# ioam3358 register map
Registers are 32-bit, access not given, no defined reset value unless marked. A register's access mark holds for its fields unless they carry their own. Addresses are absolute; registers are grouped by the start of their names; [hi:lo] are bit positions; {n}, {i} and the like mark numbered series; 'fields as' and 'values as' point back to an identical list.

## PWMSS
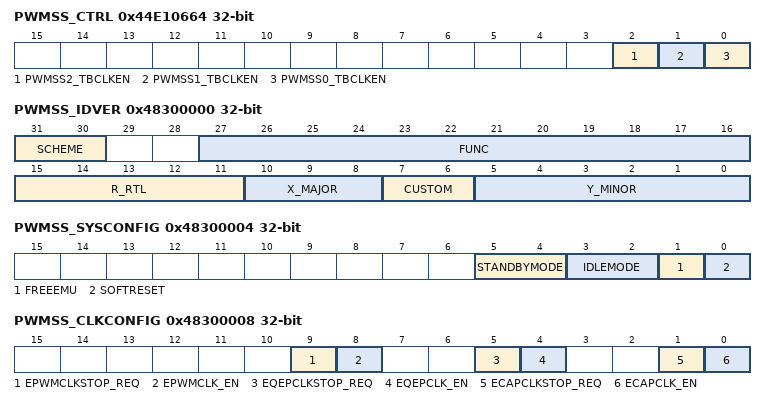
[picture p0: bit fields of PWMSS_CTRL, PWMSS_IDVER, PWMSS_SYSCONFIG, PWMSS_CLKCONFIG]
0x44E10664 PWMSS_CTRL
  [2] PWMSS2_TBCLKEN, [1] PWMSS1_TBCLKEN, [0] PWMSS0_TBCLKEN
0x48300000 PWMSS_IDVER
  [31:30] SCHEME, [27:16] FUNC, [15:11] R_RTL, [10:8] X_MAJOR, [7:6] CUSTOM, [5:0] Y_MINOR
0x48300004 PWMSS_SYSCONFIG
  [5:4] STANDBYMODE, [3:2] IDLEMODE, [1] FREEEMU, [0] SOFTRESET
0x48300008 PWMSS_CLKCONFIG
  [9] EPWMCLKSTOP_REQ, [8] EPWMCLK_EN, [5] EQEPCLKSTOP_REQ, [4] EQEPCLK_EN, [1] ECAPCLKSTOP_REQ, [0] ECAPCLK_EN
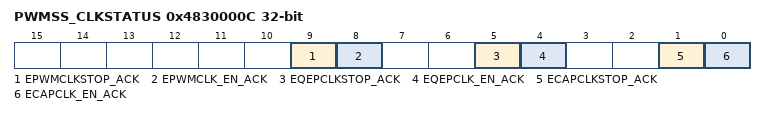
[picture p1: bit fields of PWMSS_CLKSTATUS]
0x4830000C PWMSS_CLKSTATUS
  [9] EPWMCLKSTOP_ACK, [8] EPWMCLK_EN_ACK, [5] EQEPCLKSTOP_ACK, [4] EQEPCLK_EN_ACK, [1] ECAPCLKSTOP_ACK, [0] ECAPCLK_EN_ACK

## MREQPRIO
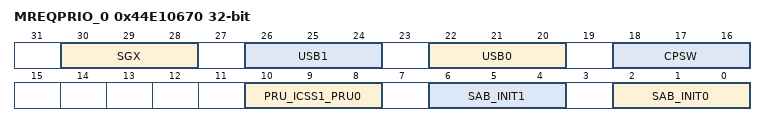
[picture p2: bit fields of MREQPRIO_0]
0x44E10670 MREQPRIO_0
  [30:28] SGX, [26:24] USB1, [22:20] USB0, [18:16] CPSW, [10:8] PRU_ICSS1_PRU0, [6:4] SAB_INIT1, [2:0] SAB_INIT0
0x44E10674 MREQPRIO_1
  [2:0] EXP

## HW
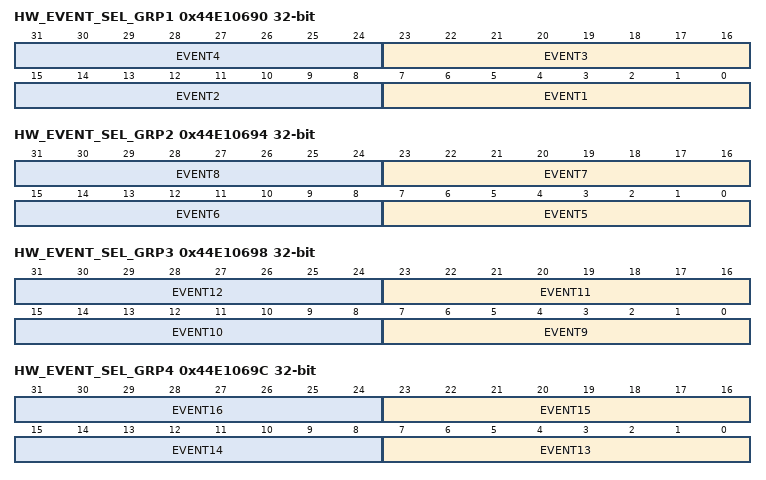
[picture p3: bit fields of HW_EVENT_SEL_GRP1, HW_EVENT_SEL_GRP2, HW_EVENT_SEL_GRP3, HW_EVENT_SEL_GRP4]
0x44E10690 HW_EVENT_SEL_GRP1
  [8n-1:8n-8] EVENT{n} (n=1..4)
0x44E10694 HW_EVENT_SEL_GRP2
  [8n-33:8n-40] EVENT{n} (n=5..8)
0x44E10698 HW_EVENT_SEL_GRP3
  [8n-65:8n-72] EVENT{n} (n=9..12)
0x44E1069C HW_EVENT_SEL_GRP4
  [8n-97:8n-104] EVENT{n} (n=13..16)

## MPUSS
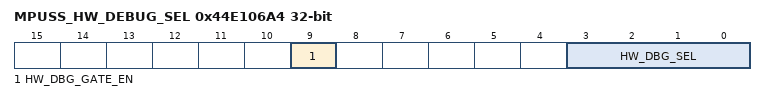
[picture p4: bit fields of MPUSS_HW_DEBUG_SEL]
0x44E106A4 MPUSS_HW_DEBUG_SEL
  [9] HW_DBG_GATE_EN, [3:0] HW_DBG_SEL
0x44E106A8 MPUSS_HW_DBG_INFO

## VDD
0x44E10770 VDD_MPU_OPP_050
  [23:0] NTARGET
0x44E10774 VDD_MPU_OPP_100
  [23:0] NTARGET
0x44E10778 VDD_MPU_OPP_120
  [23:0] NTARGET
0x44E1077C VDD_MPU_OPP_TURBO
  [23:0] NTARGET
0x44E107B8 VDD_CORE_OPP_050
  [23:0] NTARGET
0x44E107BC VDD_CORE_OPP_100
  [23:0] NTARGET

## DDR
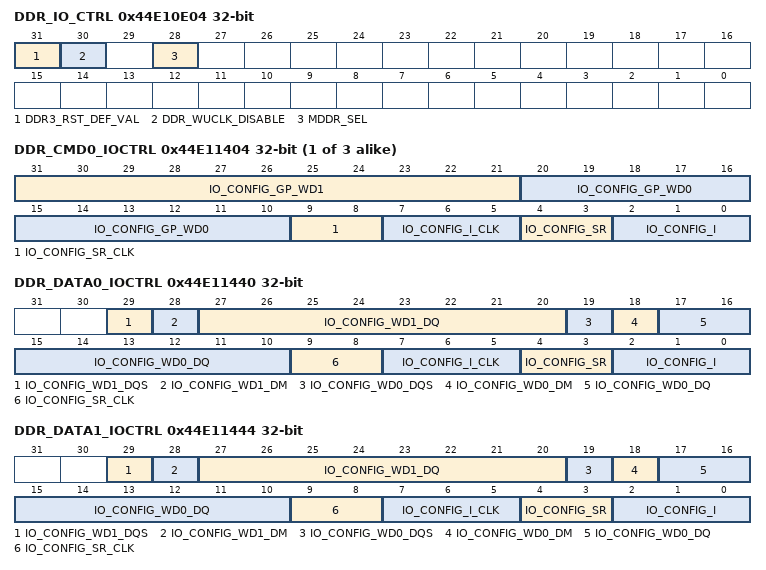
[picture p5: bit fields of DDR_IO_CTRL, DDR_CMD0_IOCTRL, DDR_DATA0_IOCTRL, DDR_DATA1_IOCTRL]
0x44E10E04 DDR_IO_CTRL
  [31] DDR3_RST_DEF_VAL, [30] DDR_WUCLK_DISABLE, [28] MDDR_SEL
0x44E1131C DDR_CKE_CTRL
  [0] DDR_CKE_CTRL
{0x44E11404+4i} DDR_CMD{i}_IOCTRL (i=0..2)
  [31:21] IO_CONFIG_GP_WD1, [20:10] IO_CONFIG_GP_WD0, [9:8] IO_CONFIG_SR_CLK, [7:5] IO_CONFIG_I_CLK, [4:3] IO_CONFIG_SR, [2:0] IO_CONFIG_I
0x44E11440 DDR_DATA0_IOCTRL
  [29] IO_CONFIG_WD1_DQS, [28] IO_CONFIG_WD1_DM, [27:20] IO_CONFIG_WD1_DQ, [19] IO_CONFIG_WD0_DQS, [18] IO_CONFIG_WD0_DM, [17:10] IO_CONFIG_WD0_DQ, [9:8] IO_CONFIG_SR_CLK, [7:5] IO_CONFIG_I_CLK, [4:3] IO_CONFIG_SR, [2:0] IO_CONFIG_I
0x44E11444 DDR_DATA1_IOCTRL
  fields as DDR_DATA0_IOCTRL

## TPCC
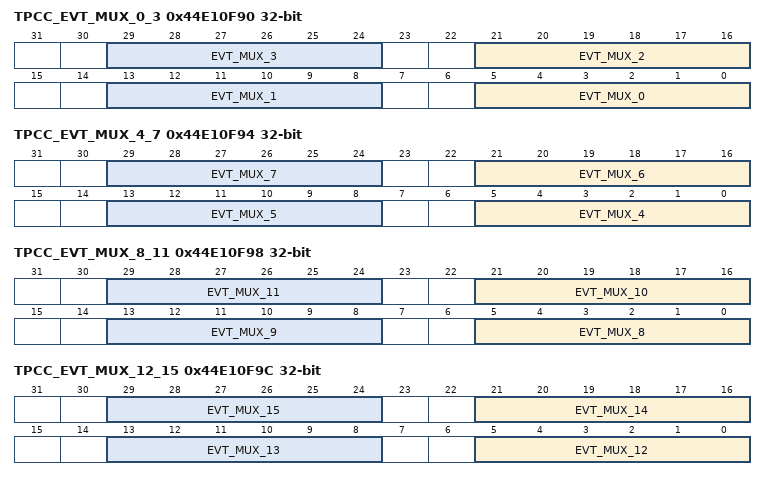
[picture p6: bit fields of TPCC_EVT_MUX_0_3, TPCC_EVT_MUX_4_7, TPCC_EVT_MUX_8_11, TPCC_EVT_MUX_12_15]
0x44E10F90 TPCC_EVT_MUX_0_3
  [8n+5:8n] EVT_MUX_{n} (n=0..3)
0x44E10F94 TPCC_EVT_MUX_4_7
  [8n-27:8n-32] EVT_MUX_{n} (n=4..7)
0x44E10F98 TPCC_EVT_MUX_8_11
  [8n-59:8n-64] EVT_MUX_{n} (n=8..11)
0x44E10F9C TPCC_EVT_MUX_12_15
  [8n-91:8n-96] EVT_MUX_{n} (n=12..15)
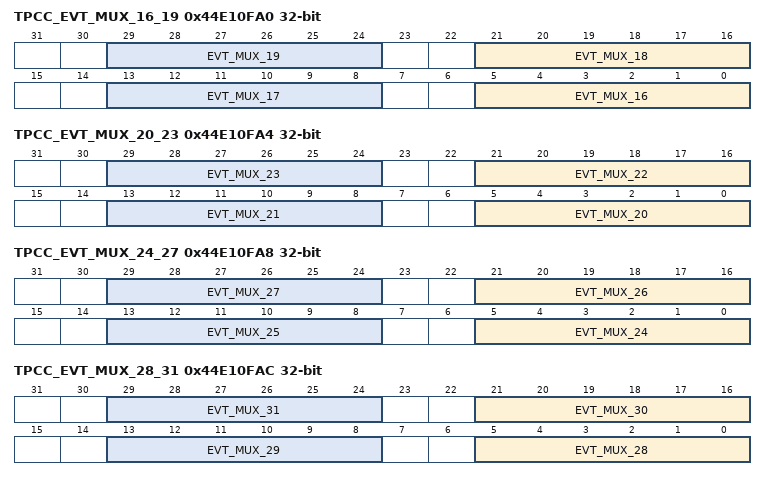
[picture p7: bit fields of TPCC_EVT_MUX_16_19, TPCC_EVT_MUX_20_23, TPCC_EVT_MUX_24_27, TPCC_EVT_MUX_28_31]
0x44E10FA0 TPCC_EVT_MUX_16_19
  [8n-123:8n-128] EVT_MUX_{n} (n=16..19)
0x44E10FA4 TPCC_EVT_MUX_20_23
  [8n-155:8n-160] EVT_MUX_{n} (n=20..23)
0x44E10FA8 TPCC_EVT_MUX_24_27
  [8n-187:8n-192] EVT_MUX_{n} (n=24..27)
0x44E10FAC TPCC_EVT_MUX_28_31
  [8n-219:8n-224] EVT_MUX_{n} (n=28..31)
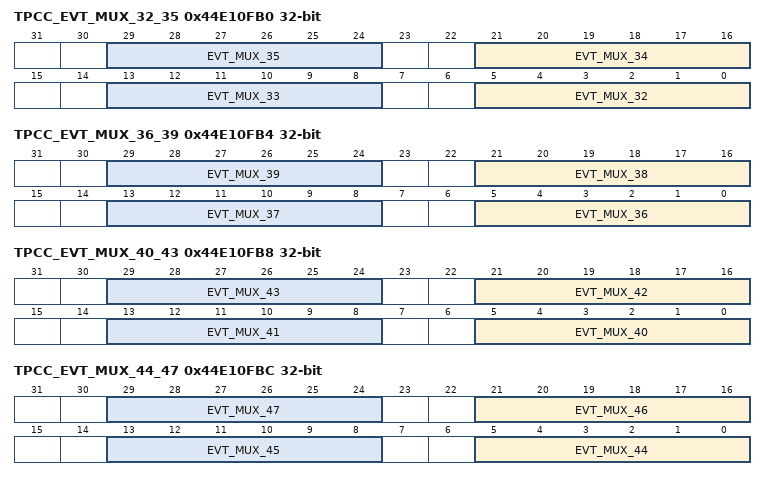
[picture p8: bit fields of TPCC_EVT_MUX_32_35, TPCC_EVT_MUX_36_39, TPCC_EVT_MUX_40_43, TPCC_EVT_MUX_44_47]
0x44E10FB0 TPCC_EVT_MUX_32_35
  [8n-251:8n-256] EVT_MUX_{n} (n=32..35)
0x44E10FB4 TPCC_EVT_MUX_36_39
  [8n-283:8n-288] EVT_MUX_{n} (n=36..39)
0x44E10FB8 TPCC_EVT_MUX_40_43
  [8n-315:8n-320] EVT_MUX_{n} (n=40..43)
0x44E10FBC TPCC_EVT_MUX_44_47
  [8n-347:8n-352] EVT_MUX_{n} (n=44..47)
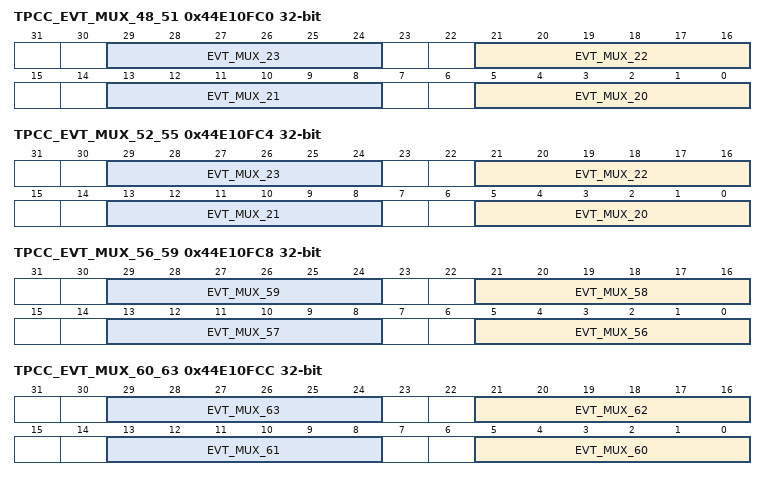
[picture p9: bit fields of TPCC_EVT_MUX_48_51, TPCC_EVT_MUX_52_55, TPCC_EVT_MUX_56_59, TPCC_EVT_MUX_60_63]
0x44E10FC0 TPCC_EVT_MUX_48_51
  [8n-155:8n-160] EVT_MUX_{n} (n=20..23)
0x44E10FC4 TPCC_EVT_MUX_52_55
  [8n-155:8n-160] EVT_MUX_{n} (n=20..23)
0x44E10FC8 TPCC_EVT_MUX_56_59
  [8n-443:8n-448] EVT_MUX_{n} (n=56..59)
0x44E10FCC TPCC_EVT_MUX_60_63
  [8n-475:8n-480] EVT_MUX_{n} (n=60..63)

## EDMATC0
0x49800000 EDMATC0_PID
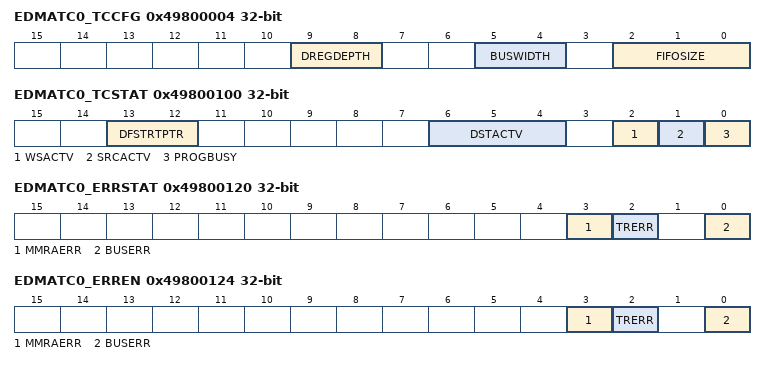
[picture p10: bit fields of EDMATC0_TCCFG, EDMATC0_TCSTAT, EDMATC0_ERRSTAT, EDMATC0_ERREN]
0x49800004 EDMATC0_TCCFG
  [9:8] DREGDEPTH, [5:4] BUSWIDTH, [2:0] FIFOSIZE
0x49800100 EDMATC0_TCSTAT
  [13:12] DFSTRTPTR, [6:4] DSTACTV, [2] WSACTV, [1] SRCACTV, [0] PROGBUSY
0x49800120 EDMATC0_ERRSTAT
  [3] MMRAERR, [2] TRERR, [0] BUSERR
0x49800124 EDMATC0_ERREN
  [3] MMRAERR, [2] TRERR, [0] BUSERR
0x49800128 EDMATC0_ERRCLR
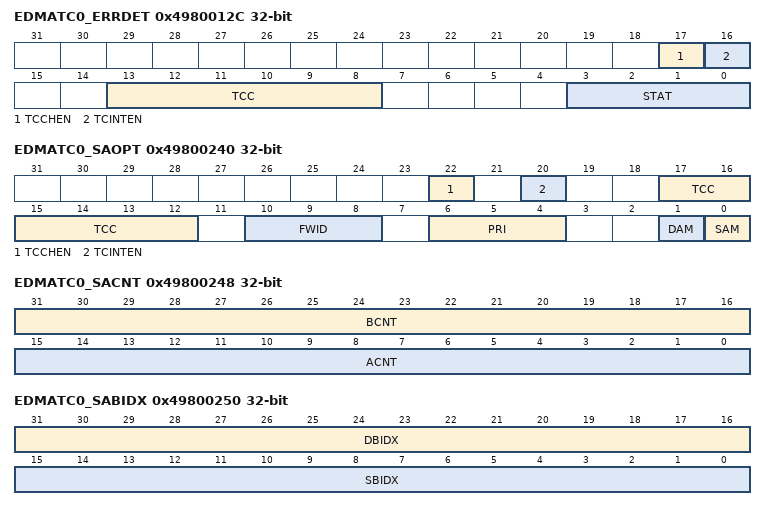
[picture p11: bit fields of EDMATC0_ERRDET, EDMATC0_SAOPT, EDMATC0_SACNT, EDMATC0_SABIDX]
0x4980012C EDMATC0_ERRDET
  [17] TCCHEN, [16] TCINTEN, [13:8] TCC, [3:0] STAT
0x49800130 EDMATC0_ERRCMD
0x49800140 EDMATC0_RDRATE
  [2:0] RDRATE
0x49800240 EDMATC0_SAOPT
  [22] TCCHEN, [20] TCINTEN, [17:12] TCC, [10:8] FWID, [6:4] PRI, [1] DAM, [0] SAM
0x49800244 EDMATC0_SASRC
0x49800248 EDMATC0_SACNT
  [31:16] BCNT, [15:0] ACNT
0x49800250 EDMATC0_SABIDX
  [31:16] DBIDX, [15:0] SBIDX
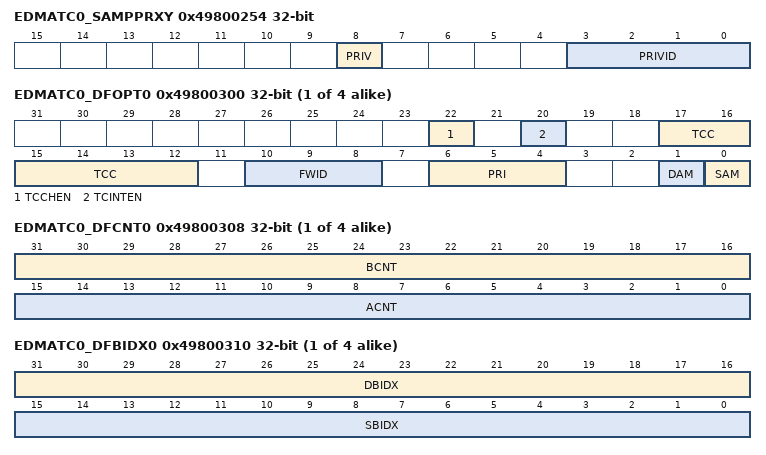
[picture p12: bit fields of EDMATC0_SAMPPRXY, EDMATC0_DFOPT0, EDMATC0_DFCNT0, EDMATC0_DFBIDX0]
0x49800254 EDMATC0_SAMPPRXY
  [8] PRIV, [3:0] PRIVID
0x49800258 EDMATC0_SACNTRLD
  [15:0] ACNTRLD
0x4980025C EDMATC0_SASRCBREF
0x49800280 EDMATC0_DFCNTRLD
  [15:0] ACNTRLD
0x49800288 EDMATC0_DFDSTBREF
{0x49800300+0x40*i} EDMATC0_DFOPT{i} (i=0..3)
  fields as EDMATC0_SAOPT
{0x49800308+0x40*i} EDMATC0_DFCNT{i} (i=0..3)
  [31:16] BCNT, [15:0] ACNT
{0x4980030C+0x40*i} EDMATC0_DFDST{i} (i=0..3)
{0x49800310+0x40*i} EDMATC0_DFBIDX{i} (i=0..3)
  [31:16] DBIDX, [15:0] SBIDX
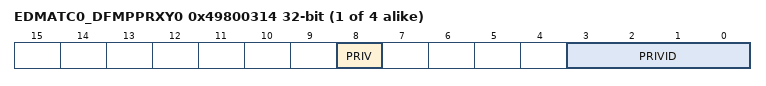
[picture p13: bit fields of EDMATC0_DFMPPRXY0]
{0x49800314+0x40*i} EDMATC0_DFMPPRXY{i} (i=0..3)
  [8] PRIV, [3:0] PRIVID
